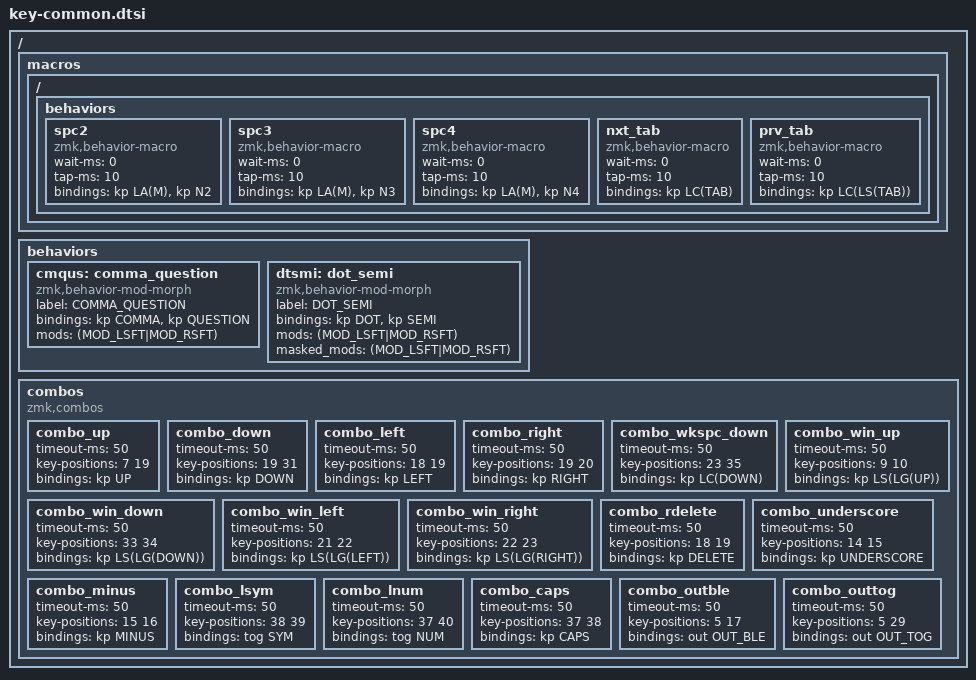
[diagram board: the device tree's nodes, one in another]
/ {
    // macros
    macros {
      ZMK_MACRO(hello, // hello world
        wait-ms = <0>;
        tap-ms  = <10>;
        bindings = <&kp LS(H) &kp E &kp L &kp L &kp O>
        , <&kp COMMA>
        , <&kp W &kp O &kp R &kp L &kp D &kp EXCL>;
      )

      ZMK_MACRO(encoder, // for encoder switch press
        wait-ms = <0>;
        tap-ms  = <10>;
        bindings = <&kp LS(I) &kp SPACE &kp A &kp M &kp SPACE &kp A &kp SPACE>
        , <&kp E &kp N &kp C &kp O &kp D &kp E &kp R>;
      )

      ZMK_MACRO(spc1, // for spacemacs window nav, Alt+M+1
        wait-ms = <0>;
        tap-ms  = <10>;
        bindings = <&kp LA(M) &kp N1>;
      )
    
      ZMK_MACRO(spc2,
        wait-ms = <0>;
        tap-ms  = <10>;
        bindings = <&kp LA(M) &kp N2>;
      )
    
      ZMK_MACRO(spc3,
        wait-ms = <0>;
        tap-ms  = <10>;
        bindings = <&kp LA(M) &kp N3>;
      )

      ZMK_MACRO(spc4,
        wait-ms = <0>;
        tap-ms  = <10>;
        bindings = <&kp LA(M) &kp N4>;
      )

      ZMK_MACRO(nxt_tab,
        wait-ms = <0>;
        tap-ms  = <10>;
        bindings = <&kp LC(TAB)>;
      )

      ZMK_MACRO(prv_tab,
        wait-ms = <0>;
        tap-ms  = <10>;
        bindings = <&kp LC(LS(TAB))>;
      )
    };
   
    // custom shift using mod-morph 
    behaviors {
      cmqus: comma_question {
        compatible = "zmk,behavior-mod-morph";
        label = "COMMA_QUESTION";
        #binding-cells = <0>;
        bindings = <&kp COMMA>, <&kp QUESTION>;
        mods = <(MOD_LSFT|MOD_RSFT)>;
      };

      dtsmi: dot_semi {
        compatible = "zmk,behavior-mod-morph";
        label = "DOT_SEMI";
        #binding-cells = <0>;
        bindings = <&kp DOT>, <&kp SEMI>;
        mods = <(MOD_LSFT|MOD_RSFT)>;
        masked_mods = <(MOD_LSFT|MOD_RSFT)>; // don't send shift
      };
    };

    // combos
    combos {
        compatible = "zmk,combos";
        // right hand 
        combo_up {
            timeout-ms = <50>;
            key-positions = <7 19>;
            bindings = <&kp UP>;
        };
        
         combo_down {
            timeout-ms = <50>;
            key-positions = <19 31>;
            bindings = <&kp DOWN>;
        };
        
         combo_left {
            timeout-ms = <50>;
            key-positions = <18 19>;
            bindings = <&kp LEFT>;
        };
        
         combo_right {
            timeout-ms = <50>;
            key-positions = <19 20>;
            bindings = <&kp RIGHT>;
        };
        
         combo_wkspc_down {
            timeout-ms = <50>;
            key-positions = <23 35>;
            bindings = <&kp LC(DOWN)>;
        };

         combo_win_up {
            timeout-ms = <50>;
            key-positions = <9 10>;
            bindings = <&kp LS(LG(UP))>;
        };
        
         combo_win_down {
            timeout-ms = <50>;
            key-positions = <33 34>;
            bindings = <&kp LS(LG(DOWN))>;
        };

         combo_win_left {
            timeout-ms = <50>;
            key-positions = <21 22>;
            bindings = <&kp LS(LG(LEFT))>;
        };

         combo_win_right {
            timeout-ms = <50>;
            key-positions = <22 23>;
            bindings = <&kp LS(LG(RIGHT))>;
        };
 
         combo_rdelete {
            timeout-ms = <50>;
            key-positions = <18 19>;
            bindings = <&kp DELETE>;
        };
 
        // left hand 
        // symbols
        combo_underscore {
            timeout-ms = <50>;
            key-positions = <14 15>;
            bindings = <&kp UNDERSCORE>;
        };

        combo_minus {
            timeout-ms = <50>;
            key-positions = <15 16>;
            bindings = <&kp MINUS>;
        };

        // others
        combo_lsym {
            timeout-ms = <50>;
            key-positions = <38 39>;
            bindings = <&tog SYM>;
        };

        combo_lnum {
            timeout-ms = <50>;
            key-positions = <37 40>;
            bindings = <&tog NUM>;
        };

        combo_caps {
            timeout-ms = <50>;
            key-positions = <37 38>;
            bindings = <&kp CAPS>;
        };

        combo_outble {
            timeout-ms = <50>;
            key-positions = <5 17>;
            bindings = <&out OUT_BLE>;
        };

        combo_outtog {
            timeout-ms = <50>;
            key-positions = <5 29>;
            bindings = <&out OUT_TOG>;
        };

        // ble selection
       
    };
};
